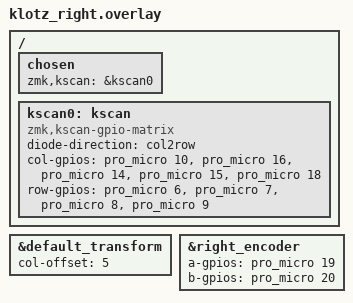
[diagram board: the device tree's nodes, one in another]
/*
 * Copyright (c) 2020 Pete Johanson
 *
 * SPDX-License-Identifier: MIT
 */

#include "klotz.dtsi"

/ {
	chosen {
		zmk,kscan = &kscan0;
        };

	kscan0: kscan {
		compatible = "zmk,kscan-gpio-matrix";
		diode-direction = "col2row";
                col-gpios
                        = <&pro_micro 10 GPIO_ACTIVE_HIGH>
                        , <&pro_micro 16 GPIO_ACTIVE_HIGH>
                        , <&pro_micro 14 GPIO_ACTIVE_HIGH>
                        , <&pro_micro 15 GPIO_ACTIVE_HIGH>
                        , <&pro_micro 18 GPIO_ACTIVE_HIGH>                
                        ;
                row-gpios
                        = <&pro_micro 6 (GPIO_ACTIVE_HIGH | GPIO_PULL_DOWN)>
                        , <&pro_micro 7 (GPIO_ACTIVE_HIGH | GPIO_PULL_DOWN)>
                        , <&pro_micro 8 (GPIO_ACTIVE_HIGH | GPIO_PULL_DOWN)>
                        , <&pro_micro 9 (GPIO_ACTIVE_HIGH | GPIO_PULL_DOWN)>
                        ;
	};
};

&default_transform {
	col-offset = <5>;
};

&right_encoder {
        a-gpios = <&pro_micro 19 (GPIO_ACTIVE_HIGH | GPIO_PULL_UP)>;
        b-gpios = <&pro_micro 20 (GPIO_ACTIVE_HIGH | GPIO_PULL_UP)>;
	status = "okay";
};
